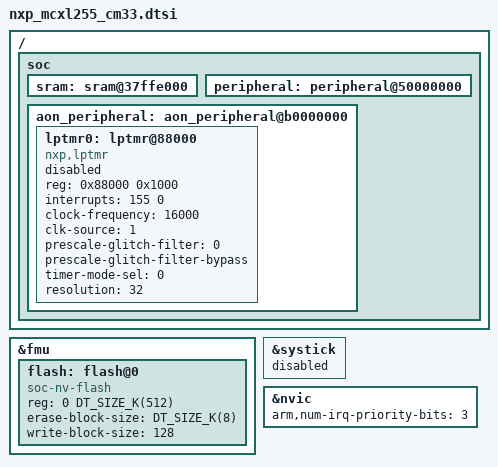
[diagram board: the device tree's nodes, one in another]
/*
 * Copyright 2025 NXP
 *
 * SPDX-License-Identifier: Apache-2.0
 */

#include <mem.h>

/ {
	soc {
		sram: sram@37ffe000 {
			ranges = <0x27ffe000 0x37ffe000 0x20000>,
				 <0xa1000000 0xb1000000 0x8000>;
		};

		peripheral: peripheral@50000000 {
			ranges = <0x0 0x50000000 0x10000000>;
		};

		aon_peripheral: aon_peripheral@b0000000 {
			ranges = <0x0 0xb0000000 0x10000000>;
		};
	};
};

#include "nxp_mcxl.dtsi"
#include "nxp_mcxl_aon.dtsi"

&fmu {
	flash: flash@0 {
		compatible = "soc-nv-flash";
		reg = <0 DT_SIZE_K(512)>;
		erase-block-size = <DT_SIZE_K(8)>;
		write-block-size = <128>;
	};
};

&systick {
	status = "disabled";
};

&nvic {
	arm,num-irq-priority-bits = <3>;
};

&aon_peripheral {
	lptmr0: lptmr@88000 {
		compatible = "nxp,lptmr";
		reg = <0x88000 0x1000>;
		interrupts = <155 0>;
		clock-frequency = <16000>;
		clk-source = <1>;
		prescale-glitch-filter = <0>;
		prescale-glitch-filter-bypass;
		timer-mode-sel = <0>;
		resolution = <32>;
		status = "disabled";
	};
};
